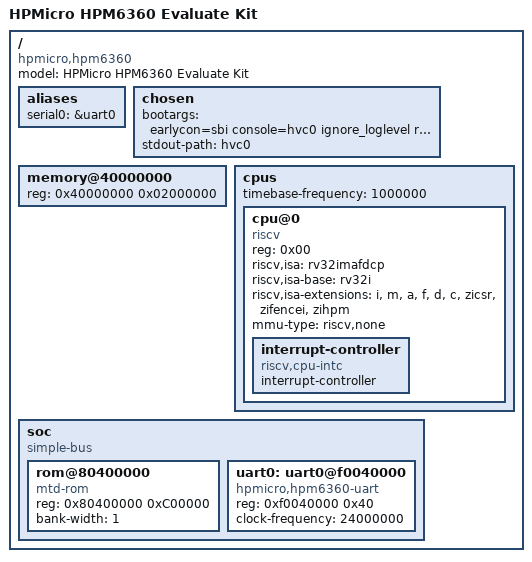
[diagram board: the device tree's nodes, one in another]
/dts-v1/;

/ {
	#address-cells = <0x01>;
	#size-cells = <0x01>;
	compatible = "hpmicro,hpm6360";
	model = "HPMicro HPM6360 Evaluate Kit";

	aliases {
		serial0 = &uart0;
	};

	chosen {
		bootargs = "earlycon=sbi console=hvc0 ignore_loglevel rootwait root=/dev/mtdblock0";
		stdout-path = "hvc0";
	};

	memory@40000000 {
		device_type = "memory";
		reg = <0x40000000 0x02000000>;
	};

	cpus {
		#address-cells = <0x01>;
		#size-cells = <0x00>;
		timebase-frequency = <1000000>;

		cpu@0 {
			phandle = <0x01>;
			device_type = "cpu";
			reg = <0x00>;
			status = "okay";
			compatible = "riscv";
			riscv,isa = "rv32imafdcp";
			riscv,isa-base = "rv32i";
			riscv,isa-extensions = "i", "m", "a", "f", "d", "c", "zicsr",
					       "zifencei", "zihpm";
			mmu-type = "riscv,none";

			interrupt-controller {
				#interrupt-cells = <0x01>;
				interrupt-controller;
				compatible = "riscv,cpu-intc";
			};
		};
	};

	soc {
		#address-cells = <0x01>;
		#size-cells = <0x01>;
		compatible = "simple-bus";
		ranges;

		rom@80400000 {
			compatible = "mtd-rom";
			reg = <0x80400000 0xC00000>;
			bank-width = <1>;
		};

		uart0: uart0@f0040000 {
			compatible = "hpmicro,hpm6360-uart";
			reg = <0xf0040000 0x40>;
			clock-frequency = <24000000>;
			status = "okay";
		};
	};
};
